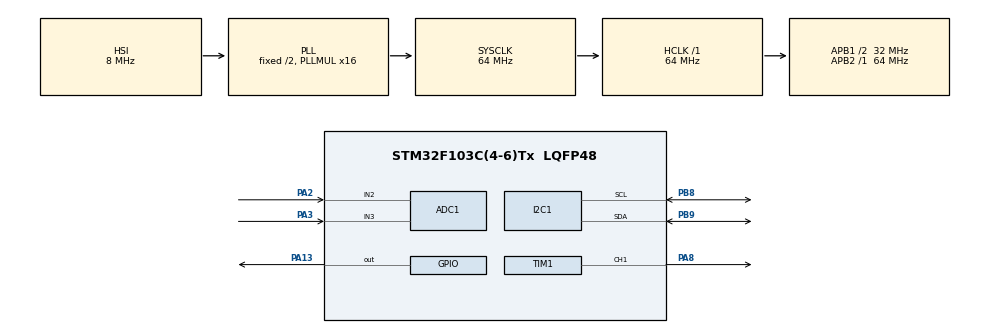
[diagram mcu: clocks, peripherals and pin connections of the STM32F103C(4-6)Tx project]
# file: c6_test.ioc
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ADC1.Channel-0\#ChannelRegularConversion=ADC_CHANNEL_2
ADC1.Channel-1\#ChannelRegularConversion=ADC_CHANNEL_3
ADC1.DataAlign=ADC_DATAALIGN_RIGHT
ADC1.DiscontinuousConvMode=DISABLE
ADC1.ExternalTrigConv=ADC_EXTERNALTRIGCONV_T1_CC1
ADC1.NbrOfConversion=2
ADC1.NbrOfConversionFlag=1
ADC1.Rank-0\#ChannelRegularConversion=1
ADC1.Rank-1\#ChannelRegularConversion=2
ADC1.SamplingTime-0\#ChannelRegularConversion=ADC_SAMPLETIME_71CYCLES_5
ADC1.SamplingTime-1\#ChannelRegularConversion=ADC_SAMPLETIME_71CYCLES_5
ADC1.master=1
Dma.ADC1.0.Direction=DMA_PERIPH_TO_MEMORY
Dma.ADC1.0.Instance=DMA1_Channel1
Dma.ADC1.0.MemDataAlignment=DMA_MDATAALIGN_HALFWORD
Dma.ADC1.0.MemInc=DMA_MINC_ENABLE
Dma.ADC1.0.Mode=DMA_CIRCULAR
Dma.ADC1.0.PeriphDataAlignment=DMA_PDATAALIGN_HALFWORD
Dma.ADC1.0.PeriphInc=DMA_PINC_DISABLE
Dma.ADC1.0.Priority=DMA_PRIORITY_LOW
Dma.Request0=ADC1
Mcu.Family=STM32F1
Mcu.Name=STM32F103C(4-6)Tx
Mcu.Package=LQFP48
NVIC.DMA1_Channel1_IRQn=true\:0\:0\:false\:false\:true\:false\:true
NVIC.PriorityGroup=NVIC_PRIORITYGROUP_4
NVIC.TIM1_UP_IRQn=true\:0\:0\:false\:false\:true\:true\:true
PA13.PinState=GPIO_PIN_RESET
PA13.Signal=GPIO_Output
PA2.Signal=ADCx_IN2
PA3.Signal=ADCx_IN3
PA8.Signal=S_TIM1_CH1
PB8.Mode=I2C
PB8.Signal=I2C1_SCL
PB9.Mode=I2C
PB9.Signal=I2C1_SDA
ProjectManager.HeapSize=0x200
ProjectManager.StackSize=0x400
ProjectManager.TargetToolchain=Makefile
RCC.ADCPresc=RCC_ADCPCLK2_DIV6
RCC.AHBFreq_Value=64000000
RCC.APB1CLKDivider=RCC_HCLK_DIV2
RCC.APB1Freq_Value=32000000
RCC.APB1TimFreq_Value=64000000
RCC.APB2Freq_Value=64000000
RCC.APB2TimFreq_Value=64000000
RCC.HCLKFreq_Value=64000000
RCC.PLLMUL=RCC_PLL_MUL16
RCC.SYSCLKFreq_VALUE=64000000
RCC.SYSCLKSource=RCC_SYSCLKSOURCE_PLLCLK
RCC.USBFreq_Value=64000000
SH.ADCx_IN2.0=ADC1_IN2,IN2
SH.ADCx_IN3.0=ADC1_IN3,IN3
SH.S_TIM1_CH1.0=TIM1_CH1,Output Compare1 CH1
TIM1.Channel-Output\ Compare1\ CH1=TIM_CHANNEL_1
TIM1.OCMode_1=TIM_OCMODE_TOGGLE
TIM1.Period=639
TIM1.Prescaler=999
TIM1.Pulse-Output\ Compare1\ CH1=50
TIM1.TIM_MasterOutputTrigger=TIM_TRGO_UPDATE
TIM1.TIM_MasterSlaveMode=TIM_MASTERSLAVEMODE_DISABLE
VP_SYS_VS_ND.Mode=No_Debug
VP_TIM1_VS_ClockSourceINT.Mode=Internal
board=custom

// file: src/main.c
/* USER CODE BEGIN Header */
/**
  ******************************************************************************
  * @file           : main.c
  * @brief          : Main program body
  ******************************************************************************
  * @attention
  *
  * <h2><center>&copy; Copyright (c) 2021 STMicroelectronics.
  * All rights reserved.</center></h2>
  *
  * This software component is licensed by ST under BSD 3-Clause license,
  * the "License"; You may not use this file except in compliance with the
  * License. You may obtain a copy of the License at:
  *                        opensource.org/licenses/BSD-3-Clause
  *
  ******************************************************************************
  */
/* USER CODE END Header */
#include "main.h"

ADC_HandleTypeDef hadc1;
DMA_HandleTypeDef hdma_adc1;

I2C_HandleTypeDef hi2c1;

TIM_HandleTypeDef htim1;

/* USER CODE BEGIN PV */
static const uint8_t NPA_201 = 0x27; // Use 8-bit address
uint16_t value_adc[2];
HAL_StatusTypeDef ret;
uint8_t buf[16];
int16_t P, T, Pconv, Tconv;
float temp_c;
/* USER CODE END PV */

void SystemClock_Config(void);
static void MX_GPIO_Init(void);
static void MX_DMA_Init(void);
static void MX_TIM1_Init(void);
static void MX_ADC1_Init(void);
static void MX_I2C1_Init(void);

int main(void)
{

  /* MCU Configuration--------------------------------------------------------*/

  /* Reset of all peripherals, Initializes the Flash interface and the Systick. */
  HAL_Init();

  /* Configure the system clock */
  SystemClock_Config();

  /* Initialize all configured peripherals */
  MX_GPIO_Init();
  MX_DMA_Init();
  MX_TIM1_Init();
  MX_ADC1_Init();
  MX_I2C1_Init();
  /* USER CODE BEGIN 2 */
  HAL_TIM_Base_Start_IT(&htim1);
  HAL_ADC_Start_DMA(&hadc1, (uint32_t*)&value_adc, 2);
  HAL_ADCEx_Calibration_Start(&hadc1);
  HAL_TIM_OC_Start(&htim1, TIM_CHANNEL_1);
  /*HAL_TIM_Base_Start_IT(&htim3);*/
  /* USER CODE END 2 */

  /* Infinite loop */
  while (1)
  {

  }
}

void SystemClock_Config(void)
{
  RCC_OscInitTypeDef RCC_OscInitStruct = {0};
  RCC_ClkInitTypeDef RCC_ClkInitStruct = {0};
  RCC_PeriphCLKInitTypeDef PeriphClkInit = {0};

  /** Initializes the RCC Oscillators according to the specified parameters
  * in the RCC_OscInitTypeDef structure.
  */
  RCC_OscInitStruct.OscillatorType = RCC_OSCILLATORTYPE_HSI;
  RCC_OscInitStruct.HSIState = RCC_HSI_ON;
  RCC_OscInitStruct.HSICalibrationValue = RCC_HSICALIBRATION_DEFAULT;
  RCC_OscInitStruct.PLL.PLLState = RCC_PLL_ON;
  RCC_OscInitStruct.PLL.PLLSource = RCC_PLLSOURCE_HSI_DIV2;
  RCC_OscInitStruct.PLL.PLLMUL = RCC_PLL_MUL16;
  if (HAL_RCC_OscConfig(&RCC_OscInitStruct) != HAL_OK)
  {
    Error_Handler();
  }
  /** Initializes the CPU, AHB and APB buses clocks
  */
  RCC_ClkInitStruct.ClockType = RCC_CLOCKTYPE_HCLK|RCC_CLOCKTYPE_SYSCLK
                              |RCC_CLOCKTYPE_PCLK1|RCC_CLOCKTYPE_PCLK2;
  RCC_ClkInitStruct.SYSCLKSource = RCC_SYSCLKSOURCE_PLLCLK;
  RCC_ClkInitStruct.AHBCLKDivider = RCC_SYSCLK_DIV1;
  RCC_ClkInitStruct.APB1CLKDivider = RCC_HCLK_DIV2;
  RCC_ClkInitStruct.APB2CLKDivider = RCC_HCLK_DIV1;

  if (HAL_RCC_ClockConfig(&RCC_ClkInitStruct, FLASH_LATENCY_2) != HAL_OK)
  {
    Error_Handler();
  }
  PeriphClkInit.PeriphClockSelection = RCC_PERIPHCLK_ADC;
  PeriphClkInit.AdcClockSelection = RCC_ADCPCLK2_DIV6;
  if (HAL_RCCEx_PeriphCLKConfig(&PeriphClkInit) != HAL_OK)
  {
    Error_Handler();
  }
}

static void MX_ADC1_Init(void)
{

  ADC_ChannelConfTypeDef sConfig = {0};

  /** Common config
  */
  hadc1.Instance = ADC1;
  hadc1.Init.ScanConvMode = ADC_SCAN_ENABLE;
  hadc1.Init.ContinuousConvMode = DISABLE;
  hadc1.Init.DiscontinuousConvMode = DISABLE;
  hadc1.Init.ExternalTrigConv = ADC_EXTERNALTRIGCONV_T1_CC1;
  hadc1.Init.DataAlign = ADC_DATAALIGN_RIGHT;
  hadc1.Init.NbrOfConversion = 2;
  if (HAL_ADC_Init(&hadc1) != HAL_OK)
  {
    Error_Handler();
  }
  /** Configure Regular Channel
  */
  sConfig.Channel = ADC_CHANNEL_2;
  sConfig.Rank = ADC_REGULAR_RANK_1;
  sConfig.SamplingTime = ADC_SAMPLETIME_71CYCLES_5;
  if (HAL_ADC_ConfigChannel(&hadc1, &sConfig) != HAL_OK)
  {
    Error_Handler();
  }
  /** Configure Regular Channel
  */
  sConfig.Channel = ADC_CHANNEL_3;
  sConfig.Rank = ADC_REGULAR_RANK_2;
  if (HAL_ADC_ConfigChannel(&hadc1, &sConfig) != HAL_OK)
  {
    Error_Handler();
  }

}

static void MX_I2C1_Init(void)
{

  hi2c1.Instance = I2C1;
  hi2c1.Init.ClockSpeed = 100000;
  hi2c1.Init.DutyCycle = I2C_DUTYCYCLE_2;
  hi2c1.Init.OwnAddress1 = 0;
  hi2c1.Init.AddressingMode = I2C_ADDRESSINGMODE_7BIT;
  hi2c1.Init.DualAddressMode = I2C_DUALADDRESS_DISABLE;
  hi2c1.Init.OwnAddress2 = 0;
  hi2c1.Init.GeneralCallMode = I2C_GENERALCALL_DISABLE;
  hi2c1.Init.NoStretchMode = I2C_NOSTRETCH_DISABLE;
  if (HAL_I2C_Init(&hi2c1) != HAL_OK)
  {
    Error_Handler();
  }

}

static void MX_TIM1_Init(void)
{

  TIM_ClockConfigTypeDef sClockSourceConfig = {0};
  TIM_MasterConfigTypeDef sMasterConfig = {0};
  TIM_OC_InitTypeDef sConfigOC = {0};
  TIM_BreakDeadTimeConfigTypeDef sBreakDeadTimeConfig = {0};

  htim1.Instance = TIM1;
  htim1.Init.Prescaler = 999;
  htim1.Init.CounterMode = TIM_COUNTERMODE_UP;
  htim1.Init.Period = 639;
  htim1.Init.ClockDivision = TIM_CLOCKDIVISION_DIV1;
  htim1.Init.RepetitionCounter = 0;
  htim1.Init.AutoReloadPreload = TIM_AUTORELOAD_PRELOAD_DISABLE;
  if (HAL_TIM_Base_Init(&htim1) != HAL_OK)
  {
    Error_Handler();
  }
  sClockSourceConfig.ClockSource = TIM_CLOCKSOURCE_INTERNAL;
  if (HAL_TIM_ConfigClockSource(&htim1, &sClockSourceConfig) != HAL_OK)
  {
    Error_Handler();
  }
  if (HAL_TIM_OC_Init(&htim1) != HAL_OK)
  {
    Error_Handler();
  }
  sMasterConfig.MasterOutputTrigger = TIM_TRGO_UPDATE;
  sMasterConfig.MasterSlaveMode = TIM_MASTERSLAVEMODE_DISABLE;
  if (HAL_TIMEx_MasterConfigSynchronization(&htim1, &sMasterConfig) != HAL_OK)
  {
    Error_Handler();
  }
  sConfigOC.OCMode = TIM_OCMODE_TOGGLE;
  sConfigOC.Pulse = 50;
  sConfigOC.OCPolarity = TIM_OCPOLARITY_HIGH;
  sConfigOC.OCNPolarity = TIM_OCNPOLARITY_HIGH;
  sConfigOC.OCFastMode = TIM_OCFAST_DISABLE;
  sConfigOC.OCIdleState = TIM_OCIDLESTATE_RESET;
  sConfigOC.OCNIdleState = TIM_OCNIDLESTATE_RESET;
  if (HAL_TIM_OC_ConfigChannel(&htim1, &sConfigOC, TIM_CHANNEL_1) != HAL_OK)
  {
    Error_Handler();
  }
  sBreakDeadTimeConfig.OffStateRunMode = TIM_OSSR_DISABLE;
  sBreakDeadTimeConfig.OffStateIDLEMode = TIM_OSSI_DISABLE;
  sBreakDeadTimeConfig.LockLevel = TIM_LOCKLEVEL_OFF;
  sBreakDeadTimeConfig.DeadTime = 0;
  sBreakDeadTimeConfig.BreakState = TIM_BREAK_DISABLE;
  sBreakDeadTimeConfig.BreakPolarity = TIM_BREAKPOLARITY_HIGH;
  sBreakDeadTimeConfig.AutomaticOutput = TIM_AUTOMATICOUTPUT_DISABLE;
  if (HAL_TIMEx_ConfigBreakDeadTime(&htim1, &sBreakDeadTimeConfig) != HAL_OK)
  {
    Error_Handler();
  }
  HAL_TIM_MspPostInit(&htim1);

}

static void MX_DMA_Init(void)
{

  /* DMA controller clock enable */
  __HAL_RCC_DMA1_CLK_ENABLE();

  /* DMA interrupt init */
  /* DMA1_Channel1_IRQn interrupt configuration */
  HAL_NVIC_SetPriority(DMA1_Channel1_IRQn, 0, 0);
  HAL_NVIC_EnableIRQ(DMA1_Channel1_IRQn);

}

static void MX_GPIO_Init(void)
{
  GPIO_InitTypeDef GPIO_InitStruct = {0};

  /* GPIO Ports Clock Enable */
  __HAL_RCC_GPIOA_CLK_ENABLE();
  __HAL_RCC_GPIOB_CLK_ENABLE();

  /*Configure GPIO pin Output Level */
  HAL_GPIO_WritePin(GPIOA, GPIO_PIN_13, GPIO_PIN_RESET);

  /*Configure GPIO pin : PA13 */
  GPIO_InitStruct.Pin = GPIO_PIN_13;
  GPIO_InitStruct.Mode = GPIO_MODE_OUTPUT_PP;
  GPIO_InitStruct.Pull = GPIO_NOPULL;
  GPIO_InitStruct.Speed = GPIO_SPEED_FREQ_LOW;
  HAL_GPIO_Init(GPIOA, &GPIO_InitStruct);

}

/* USER CODE BEGIN 4 */
  void HAL_TIM_PeriodElapsedCallback(TIM_HandleTypeDef *htim)
  {
    if(htim == &htim1)
    {
      HAL_GPIO_TogglePin(GPIOA, GPIO_PIN_13);
      /*HAL_ADC_Start_DMA(&hadc1, (uint32_t*)value_adc , 5);*/
    }
  }
  void HAL_ADC_ConvCpltCallback(ADC_HandleTypeDef* hadc)
  {
    /*HAL_GPIO_TogglePin(GPIOA, GPIO_PIN_13);*/
  }
/* USER CODE END 4 */

void Error_Handler(void)
{
  __disable_irq();
  while (1)
  {
  }
}

/************************ (C) COPYRIGHT STMicroelectronics *****END OF FILE****/
